# STM32H730 register map
File version: 1.8
CPU: CM7 r0p1, little endian, MPU, FPU, 4 interrupt priority bits
Registers are 32-bit, read-write, reset 0x0 unless marked. A register's access mark holds for its fields unless they carry their own. Offsets are from the block's base; [hi:lo] are bit positions; {n}, {i} and the like mark numbered series.

## CRYP — Cryptographic processor
Base 0x48021000
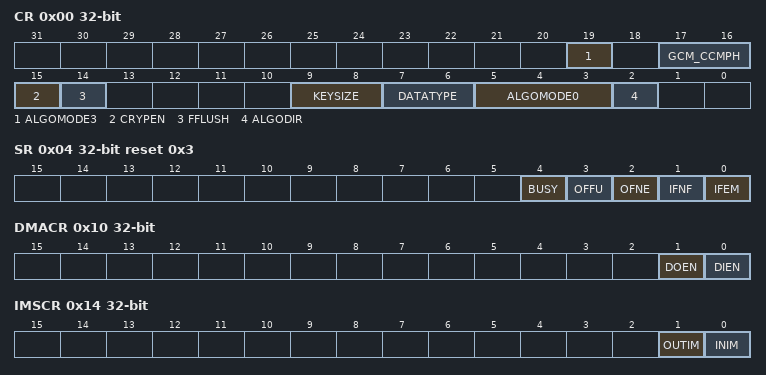
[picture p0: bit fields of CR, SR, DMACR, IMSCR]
0x00 CR access per field — control register
  [19] ALGOMODE3 rw — ALGOMODE
  [17:16] GCM_CCMPH rw
  [15] CRYPEN rw — Cryptographic processor enable
  [14] FFLUSH wo — FIFO flush
  [9:8] KEYSIZE rw — Key size selection (AES mode only)
  [7:6] DATATYPE rw — Data type selection
  [5:3] ALGOMODE0 rw — Algorithm mode
  [2] ALGODIR rw — Algorithm direction
0x04 SR ro reset 0x3 — status register
  [4] BUSY — Busy bit
  [3] OFFU — Output FIFO full
  [2] OFNE — Output FIFO not empty
  [1] IFNF — Input FIFO not full
  [0] IFEM — Input FIFO empty
0x08 DIN — data input register
  [31:0] DATAIN — Data input
0x0C DOUT ro — data output register
  [31:0] DATAOUT — Data output
0x10 DMACR — DMA control register
  [1] DOEN — DMA output enable
  [0] DIEN — DMA input enable
0x14 IMSCR — interrupt mask set/clear register
  [1] OUTIM — Output FIFO service interrupt mask
  [0] INIM — Input FIFO service interrupt mask
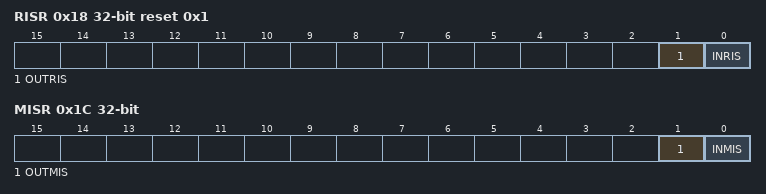
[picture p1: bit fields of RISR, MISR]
0x18 RISR ro reset 0x1 — raw interrupt status register
  [1] OUTRIS — Output FIFO service raw interrupt status
  [0] INRIS — Input FIFO service raw interrupt status
0x1C MISR ro — masked interrupt status register
  [1] OUTMIS — Output FIFO service masked interrupt status
  [0] INMIS — Input FIFO service masked interrupt status
0x20 K0LR wo — key registers
  [31:0] k2 — k224
0x24 K0RR wo — key registers
  [31:0] k — k192
0x28 K1LR wo — key registers
  [31:0] k1 — k160
0x2C K1RR wo — key registers
  [31:0] k1 — k128
0x30 K2LR wo — key registers
  [30:0] k — k96
0x34 K2RR wo — key registers
  [31:0] k — k64
0x38 K3LR wo — key registers
  [31:0] k — k32
0x3C K3RR wo — key registers
  [31:0] k — k0
0x40 IV0LR — Initialization vector register 0L
  [31:0] IV — IV31
0x44 IV0RR — initialization vector register 0R
  [31:0] IV — IV63
0x48 IV1LR — Initialization vector register 1L
  [31:0] IV — IV95
0x4C IV1RR — Initialization vector register 1R
  [31:0] IV — IV127
{0x50+4i} CSGCMCCM{i}R (i=0..7) — context swap register
{0x70+4i} CSGCM{i}R (i=0..7) — context swap register

## DBGMCU — DBGMCU address block description
Base 0x5C001000
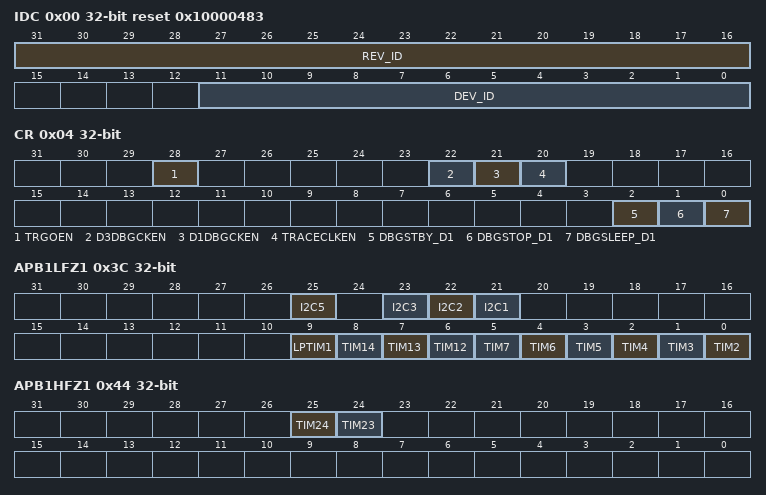
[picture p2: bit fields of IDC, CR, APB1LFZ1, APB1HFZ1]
0x00 IDC ro reset 0x10000483
  [31:16] REV_ID — Revision
  [11:0] DEV_ID — Device ID
0x04 CR
  [28] TRGOEN — External trigger output enable
  [22] D3DBGCKEN — D3 debug clock enable
  [21] D1DBGCKEN — D1 debug clock enable
  [20] TRACECLKEN — Trace port clock enable
  [2] DBGSTBY_D1 — D1 domain debug in Standby mode enable
  [1] DBGSTOP_D1 — D1 domain debug in Stop mode enable
  [0] DBGSLEEP_D1 — D1 domain debug in Sleep mode enable
0x34 APB3FZ1
  [6] WWDG1 — WWDG1 stop in debug
0x3C APB1LFZ1
  [25] I2C5 — I2C5 SMBUS timeout stop in debug
  [23] I2C3 — I2C3 SMBUS timeout stop in debug
  [22] I2C2 — I2C2 SMBUS timeout stop in debug
  [21] I2C1 — I2C1 SMBUS timeout stop in debug
  [9] LPTIM1 — LPTIM1 stop in debug
  [8] TIM14 — TIM14 stop in debug
  [7] TIM13 — TIM13 stop in debug
  [6] TIM12 — TIM12 stop in debug
  [n-2] TIM{n} (n=2..7) — TIM{n} stop in debug
0x44 APB1HFZ1
  [25] TIM24 — TIM24 stop in debug
  [24] TIM23 — TIM23 stop in debug
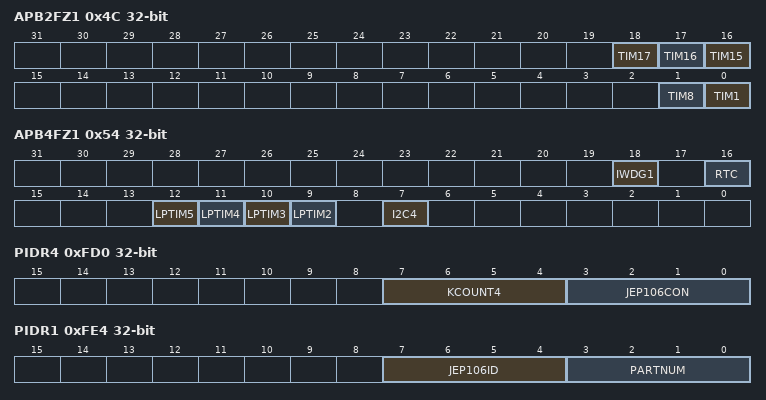
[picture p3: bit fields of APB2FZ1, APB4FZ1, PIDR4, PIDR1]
0x4C APB2FZ1
  [18] TIM17 — TIM17 stop in debug
  [17] TIM16 — TIM16 stop in debug
  [16] TIM15 — TIM15 stop in debug
  [1] TIM8 — TIM8 stop in debug
  [0] TIM1 — TIM1 stop in debug
0x54 APB4FZ1
  [18] IWDG1 — Independent watchdog for D1 stop in debug
  [16] RTC — RTC stop in debug
  [12] LPTIM5 — LPTIM5 stop in debug
  [11] LPTIM4 — LPTIM4 stop in debug
  [10] LPTIM3 — LPTIM2 stop in debug
  [9] LPTIM2 — LPTIM2 stop in debug
  [7] I2C4 — I2C4 SMBUS timeout stop in debug
0xFD0 PIDR4 ro
  [7:4] KCOUNT4 — Register file size
  [3:0] JEP106CON — JEP106 continuation code
0xFE0 PIDR0 ro
  [7:0] PARTNUM — Part number field, bits [7:0]
0xFE4 PIDR1 ro
  [7:4] JEP106ID — JEP106 identity code field, bits [3:0]
  [3:0] PARTNUM — Part number field, bits [11:8]
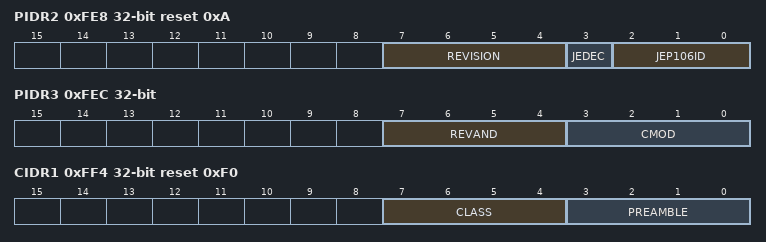
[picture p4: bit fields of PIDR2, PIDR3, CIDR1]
0xFE8 PIDR2 ro reset 0xA
  [7:4] REVISION — Component revision number
  [3] JEDEC — JEDEC assigned value
  [2:0] JEP106ID — JEP106 identity code field, bits [6:4]
0xFEC PIDR3 ro
  [7:4] REVAND — Metal fix version
  [3:0] CMOD — Customer modified
0xFF0 CIDR0 ro reset 0xD
  [7:0] PREAMBLE — Component ID field, bits [7:0]
0xFF4 CIDR1 ro reset 0xF0
  [7:4] CLASS — Component ID field, bits [15:12] - component class
  [3:0] PREAMBLE — Component ID field, bits [11:8]
0xFF8 CIDR2 ro reset 0x5
  [7:0] PREAMBLE — Component ID field, bits [23:16]
0xFFC CIDR3 ro reset 0xB1
  [7:0] PREAMBLE — Component ID field, bits [31:24]
